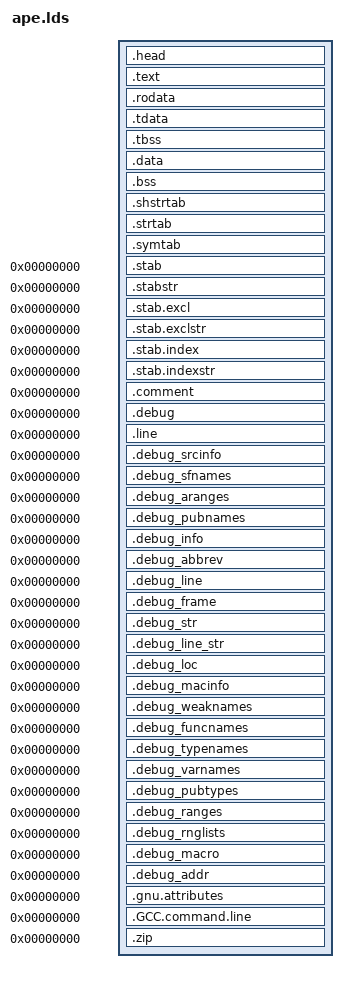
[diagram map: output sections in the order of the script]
ENTRY(_start)
PHDRS {
  Head 1 FLAGS(1|4);
  Cod 1 FLAGS(1|4);
  Rom 1 FLAGS(4);
  Tls 7 FLAGS(2|4);
  Ram 1 FLAGS(2|4);
  stack 0x6474e551 FLAGS(2|4);
}
SECTIONS {
  .head SEGMENT_START("text-segment", 0x400000) + 0 : AT(0x2000) {
    __executable_start = .;
    KEEP(*(.head))
    KEEP(*(.text.head))
    . = ALIGN(. != 0 ? 8 : 0);
    ape_phdrs = .;
    KEEP(*(.elf.phdrs))
    ape_phdrs_end = .;
    . = ALIGN(. != 0 ? 8 : 0);
    ape_note = .;
    KEEP(*(.note.openbsd.ident))
    KEEP(*(.note.netbsd.ident))
    ape_note_end = .;
    KEEP(*(.pe.header))
    ape_pe_sections = .;
    KEEP(*(.pe.sections))
    ape_pe_sections_end = .;
    KEEP(*(.macho))
    . = ALIGN(. != 0 ? 8 : 0);
    ape_macho_end = .;
    KEEP(*(.ape.loader))
    . = ALIGN(. != 0 ? 1 : 0);
    KEEP(*(.ape.pad.head))
    . = ALIGN(. != 0 ? (((1 & 4) == 4) || ((1 & 2) == 2) ? CONSTANT(COMMONPAGESIZE) : 16) : 0);
    _ehead = .;
  } :Head
  .text . : {
    BYTE(0x90)
    *(.text.real)
    KEEP(*(SORT_BY_NAME(.sort.text.real.*)))
    _ereal = .;
    . += 1;
    *(.start)
    KEEP(*(.initprologue))
    KEEP(*(SORT_BY_NAME(.init.*)))
    KEEP(*(.init))
    KEEP(*(.initepilogue))
    *(.plt)
    *(.plt.got)
    *(.iplt)
    *(.text.startup .text.startup.*)
    *(.text.exit .text.exit.*)
    *(.text.unlikely .text.*_unlikely .text.unlikely.*)
    *(SORT_BY_ALIGNMENT(.text.antiquity))
    *(SORT_BY_ALIGNMENT(.text.antiquity.*))
    KEEP(*(.textwindowsprologue))
    *(.text.windows)
    KEEP(*(.textwindowsepilogue))
    *(SORT_BY_ALIGNMENT(.text.modernity))
    *(SORT_BY_ALIGNMENT(.text.modernity.*))
    *(SORT_BY_ALIGNMENT(.text.hot))
    *(SORT_BY_ALIGNMENT(.text.hot.*))
    KEEP(*(.keep.text))
    *(.text .stub .text.*)
    KEEP(*(SORT_BY_NAME(.sort.text.*)))
    KEEP(*(.ape.pad.test));
    *(.test.unlikely)
    *(.test .test.*)
    KEEP(*(.ape.pad.privileged));
    . = ALIGN(__privileged_end > __privileged_start ? CONSTANT(COMMONPAGESIZE) : 0);
    __privileged_start = .;
    *(.privileged)
    __privileged_end = .;
    KEEP(*(.ape.pad.text))
    . = ALIGN(. != 0 ? CONSTANT(COMMONPAGESIZE) : 0);
  } :Cod
  .rodata ALIGN(CONSTANT(COMMONPAGESIZE)) : {
    KEEP(*(.rodata.pytab.0));
    KEEP(*(.rodata.pytab.1));
    KEEP(*(.rodata.pytab.2));
    *(.rodata .rodata.*)
    *(.ubsan.types)
    *(.ubsan.data)
    __notices = .;
    KEEP(*(.notice))
    BYTE(0);
    BYTE(10);
    BYTE(10);
    KEEP(*(.initroprologue))
    KEEP(*(SORT_BY_NAME(.initro.*)))
    KEEP(*(.initroepilogue))
    KEEP(*(SORT_BY_NAME(.sort.rodata.*)))
    . = ALIGN(. != 0 ? CONSTANT(COMMONPAGESIZE) : 0);
  } :Rom
  .tdata . : {
    _tdata_start = .;
    *(SORT_BY_ALIGNMENT(.tdata))
    *(SORT_BY_ALIGNMENT(.tdata.*))
    _tdata_end = .;
    KEEP(*(.ape.pad.rodata))
    . = ALIGN(. != 0 ? CONSTANT(COMMONPAGESIZE) : 0);
    _etext = .;
    PROVIDE(etext = .);
  } :Tls :Rom
  . = ALIGN(CONSTANT(COMMONPAGESIZE));
  .tbss : {
    _tbss_start = .;
    *(SORT_BY_ALIGNMENT(.tbss))
    *(SORT_BY_ALIGNMENT(.tbss.*))
    KEEP(*(.fstls))
    _tbss_end = .;
  } :Tls
  .data . : {
    KEEP(*(.dataprologue))
    *(.data .data.*)
    *(.gnu_extab)
    *(.gcc_except_table .gcc_except_table.*)
    *(.exception_ranges*)
    *(.PyRuntime)
    *(.subrs)
    KEEP(*(SORT_BY_NAME(.sort.data.*)))
    . += . > 0 ? 1 : 0;
    . = ALIGN(. != 0 ? 8 : 0);
    __got_start = .;
    *(.got)
    __got_end = .;
    *(.got.plt)
    . = ALIGN(. != 0 ? 8 : 0);
    __init_array_start = .;
    KEEP(*(.preinit_array))
    KEEP(*(SORT_BY_INIT_PRIORITY(.init_array.*)
           SORT_BY_INIT_PRIORITY(.ctors.*)))
    KEEP(*(.init_array))
    KEEP(*(.ctors))
    __init_array_end = .;
    . = ALIGN(. != 0 ? 8 : 0);
    __fini_array_start = .;
    KEEP(*(SORT_BY_INIT_PRIORITY(.fini_array.*)
           SORT_BY_INIT_PRIORITY(.dtors.*)))
    KEEP(*(.fini_array))
    KEEP(*(.dtors))
    __fini_array_end = .;
    . = ALIGN(. != 0 ? 8 : 0);
    KEEP(*(SORT_BY_NAME(.piro.relo.sort.*)))
    . = ALIGN(. != 0 ? 8 : 0);
    KEEP(*(SORT_BY_NAME(.piro.data.sort.*)))
    KEEP(*(.piro.pad.data))
    *(.igot.plt)
    KEEP(*(.dataepilogue))
    . = ALIGN(. != 0 ? CONSTANT(COMMONPAGESIZE) : 0);
    _edata = .;
    PROVIDE(edata = .);
    _ezip = .;
  } :Ram
  . = ALIGN(CONSTANT(COMMONPAGESIZE));
  .bss : {
    KEEP(*(.bssprologue))
    KEEP(*(SORT_BY_NAME(.piro.bss.init.*)))
    *(.piro.bss)
    KEEP(*(SORT_BY_NAME(.piro.bss.sort.*)))
    __piro_end = .;
    . += . > 0 ? 1 : 0;
    *(SORT_BY_ALIGNMENT(.bss))
    *(SORT_BY_ALIGNMENT(.bss.*))
    *(COMMON)
    KEEP(*(SORT_BY_NAME(.sort.bss.*)))
    KEEP(*(.bssepilogue))
    . = ALIGN(. != 0 ? CONSTANT(COMMONPAGESIZE) : 0);
  } :Ram
  . = ALIGN(CONSTANT(COMMONPAGESIZE));
  _end = .;
  PROVIDE(end = .);
  .shstrtab : { *(.shstrtab) }
  .strtab : { *(.strtab) }
  .symtab : { *(.symtab) }
  .stab 0 : { *(.stab) }
  .stabstr 0 : { *(.stabstr) }
  .stab.excl 0 : { *(.stab.excl) }
  .stab.exclstr 0 : { *(.stab.exclstr) }
  .stab.index 0 : { *(.stab.index) }
  .stab.indexstr 0 : { *(.stab.indexstr) }
  .comment 0 : { *(.comment) }
  .debug 0 : { *(.debug) }
  .line 0 : { *(.line) }
  .debug_srcinfo 0 : { *(.debug_srcinfo) }
  .debug_sfnames 0 : { *(.debug_sfnames) }
  .debug_aranges 0 : { *(.debug_aranges) }
  .debug_pubnames 0 : { *(.debug_pubnames) }
  .debug_info 0 : { *(.debug_info .gnu.linkonce.wi.*) }
  .debug_abbrev 0 : { *(.debug_abbrev) }
  .debug_line 0 : { *(.debug_line .debug_line.* .debug_line_end ) }
  .debug_frame 0 : { *(.debug_frame) }
  .debug_str 0 : { *(.debug_str) }
  .debug_line_str 0 : { *(.debug_line_str) }
  .debug_loc 0 : { *(.debug_loc) }
  .debug_macinfo 0 : { *(.debug_macinfo) }
  .debug_weaknames 0 : { *(.debug_weaknames) }
  .debug_funcnames 0 : { *(.debug_funcnames) }
  .debug_typenames 0 : { *(.debug_typenames) }
  .debug_varnames 0 : { *(.debug_varnames) }
  .debug_pubtypes 0 : { *(.debug_pubtypes) }
  .debug_ranges 0 : { *(.debug_ranges) }
  .debug_rnglists 0 : { *(.debug_rnglists) }
  .debug_macro 0 : { *(.debug_macro) }
  .debug_addr 0 : { *(.debug_addr) }
  .gnu.attributes 0 : { KEEP(*(.gnu.attributes)) }
  .GCC.command.line 0 : { *(.GCC.command.line) }
  .zip 0 : {
    KEEP(*(.zip.file))
    __zip_cdir_start = .;
    KEEP(*(.zip.cdir))
    __zip_cdir_size = . - __zip_cdir_start;
    KEEP(*(.zip.eocd))
  }
  /DISCARD/ : {
    *(.idata.ro);
    *(.idata.ro.*)
    *(.piro.data.sort.iat.*)
    *(__patchable_function_entries)
    *(.note.gnu.property)
    *(__mcount_loc)
    *(.rela.dyn)
    *(.discard)
    *(.yoink)
  }
}
ape_pe_filealignment = 512;
ape_pe_sectionalignment = 4096;
ape_pe_sizeofheaders = SIZEOF(.head);
ape_pe_sizeofimage = (((_end - __executable_start) + (ape_pe_sectionalignment) - 1) & -(ape_pe_sectionalignment));
HIDDEN(ape_elf_entry = (_start)); HIDDEN(ape_elf_entry_bcs0 = (((((((_start) >> ((0) * 8)) >> 0) & 0x7) + 0x30) << 24) | ((((((_start) >> ((0) * 8)) >> 3) & 0x7) + 0x30) << 16) | (((((((_start) >> ((0) * 8)) & 0xff) >> 6) & 0x7) + 0x30) << 8) | 0x5c)); HIDDEN(ape_elf_entry_bcs1 = (((((((_start) >> ((1) * 8)) >> 0) & 0x7) + 0x30) << 24) | ((((((_start) >> ((1) * 8)) >> 3) & 0x7) + 0x30) << 16) | (((((((_start) >> ((1) * 8)) & 0xff) >> 6) & 0x7) + 0x30) << 8) | 0x5c)); HIDDEN(ape_elf_entry_bcs2 = (((((((_start) >> ((2) * 8)) >> 0) & 0x7) + 0x30) << 24) | ((((((_start) >> ((2) * 8)) >> 3) & 0x7) + 0x30) << 16) | (((((((_start) >> ((2) * 8)) & 0xff) >> 6) & 0x7) + 0x30) << 8) | 0x5c)); HIDDEN(ape_elf_entry_bcs3 = (((((((_start) >> ((3) * 8)) >> 0) & 0x7) + 0x30) << 24) | ((((((_start) >> ((3) * 8)) >> 3) & 0x7) + 0x30) << 16) | (((((((_start) >> ((3) * 8)) & 0xff) >> 6) & 0x7) + 0x30) << 8) | 0x5c)); HIDDEN(ape_elf_entry_bcs4 = (((((((_start) >> ((4) * 8)) >> 0) & 0x7) + 0x30) << 24) | ((((((_start) >> ((4) * 8)) >> 3) & 0x7) + 0x30) << 16) | (((((((_start) >> ((4) * 8)) & 0xff) >> 6) & 0x7) + 0x30) << 8) | 0x5c)); HIDDEN(ape_elf_entry_bcs5 = (((((((_start) >> ((5) * 8)) >> 0) & 0x7) + 0x30) << 24) | ((((((_start) >> ((5) * 8)) >> 3) & 0x7) + 0x30) << 16) | (((((((_start) >> ((5) * 8)) & 0xff) >> 6) & 0x7) + 0x30) << 8) | 0x5c)); HIDDEN(ape_elf_entry_bcs6 = (((((((_start) >> ((6) * 8)) >> 0) & 0x7) + 0x30) << 24) | ((((((_start) >> ((6) * 8)) >> 3) & 0x7) + 0x30) << 16) | (((((((_start) >> ((6) * 8)) & 0xff) >> 6) & 0x7) + 0x30) << 8) | 0x5c)); HIDDEN(ape_elf_entry_bcs7 = (((((((_start) >> ((7) * 8)) >> 0) & 0x7) + 0x30) << 24) | ((((((_start) >> ((7) * 8)) >> 3) & 0x7) + 0x30) << 16) | (((((((_start) >> ((7) * 8)) & 0xff) >> 6) & 0x7) + 0x30) << 8) | 0x5c));
HIDDEN(ape_elf_phoff = (((ape_phdrs) - (0x400000)))); HIDDEN(ape_elf_phoff_bcs0 = (((((((((ape_phdrs) - (0x400000))) >> ((0) * 8)) >> 0) & 0x7) + 0x30) << 24) | ((((((((ape_phdrs) - (0x400000))) >> ((0) * 8)) >> 3) & 0x7) + 0x30) << 16) | (((((((((ape_phdrs) - (0x400000))) >> ((0) * 8)) & 0xff) >> 6) & 0x7) + 0x30) << 8) | 0x5c)); HIDDEN(ape_elf_phoff_bcs1 = (((((((((ape_phdrs) - (0x400000))) >> ((1) * 8)) >> 0) & 0x7) + 0x30) << 24) | ((((((((ape_phdrs) - (0x400000))) >> ((1) * 8)) >> 3) & 0x7) + 0x30) << 16) | (((((((((ape_phdrs) - (0x400000))) >> ((1) * 8)) & 0xff) >> 6) & 0x7) + 0x30) << 8) | 0x5c)); HIDDEN(ape_elf_phoff_bcs2 = (((((((((ape_phdrs) - (0x400000))) >> ((2) * 8)) >> 0) & 0x7) + 0x30) << 24) | ((((((((ape_phdrs) - (0x400000))) >> ((2) * 8)) >> 3) & 0x7) + 0x30) << 16) | (((((((((ape_phdrs) - (0x400000))) >> ((2) * 8)) & 0xff) >> 6) & 0x7) + 0x30) << 8) | 0x5c)); HIDDEN(ape_elf_phoff_bcs3 = (((((((((ape_phdrs) - (0x400000))) >> ((3) * 8)) >> 0) & 0x7) + 0x30) << 24) | ((((((((ape_phdrs) - (0x400000))) >> ((3) * 8)) >> 3) & 0x7) + 0x30) << 16) | (((((((((ape_phdrs) - (0x400000))) >> ((3) * 8)) & 0xff) >> 6) & 0x7) + 0x30) << 8) | 0x5c)); HIDDEN(ape_elf_phoff_bcs4 = (((((((((ape_phdrs) - (0x400000))) >> ((4) * 8)) >> 0) & 0x7) + 0x30) << 24) | ((((((((ape_phdrs) - (0x400000))) >> ((4) * 8)) >> 3) & 0x7) + 0x30) << 16) | (((((((((ape_phdrs) - (0x400000))) >> ((4) * 8)) & 0xff) >> 6) & 0x7) + 0x30) << 8) | 0x5c)); HIDDEN(ape_elf_phoff_bcs5 = (((((((((ape_phdrs) - (0x400000))) >> ((5) * 8)) >> 0) & 0x7) + 0x30) << 24) | ((((((((ape_phdrs) - (0x400000))) >> ((5) * 8)) >> 3) & 0x7) + 0x30) << 16) | (((((((((ape_phdrs) - (0x400000))) >> ((5) * 8)) & 0xff) >> 6) & 0x7) + 0x30) << 8) | 0x5c)); HIDDEN(ape_elf_phoff_bcs6 = (((((((((ape_phdrs) - (0x400000))) >> ((6) * 8)) >> 0) & 0x7) + 0x30) << 24) | ((((((((ape_phdrs) - (0x400000))) >> ((6) * 8)) >> 3) & 0x7) + 0x30) << 16) | (((((((((ape_phdrs) - (0x400000))) >> ((6) * 8)) & 0xff) >> 6) & 0x7) + 0x30) << 8) | 0x5c)); HIDDEN(ape_elf_phoff_bcs7 = (((((((((ape_phdrs) - (0x400000))) >> ((7) * 8)) >> 0) & 0x7) + 0x30) << 24) | ((((((((ape_phdrs) - (0x400000))) >> ((7) * 8)) >> 3) & 0x7) + 0x30) << 16) | (((((((((ape_phdrs) - (0x400000))) >> ((7) * 8)) & 0xff) >> 6) & 0x7) + 0x30) << 8) | 0x5c));
HIDDEN(ape_elf_shoff = (0)); HIDDEN(ape_elf_shoff_bcs0 = (((((((0) >> ((0) * 8)) >> 0) & 0x7) + 0x30) << 24) | ((((((0) >> ((0) * 8)) >> 3) & 0x7) + 0x30) << 16) | (((((((0) >> ((0) * 8)) & 0xff) >> 6) & 0x7) + 0x30) << 8) | 0x5c)); HIDDEN(ape_elf_shoff_bcs1 = (((((((0) >> ((1) * 8)) >> 0) & 0x7) + 0x30) << 24) | ((((((0) >> ((1) * 8)) >> 3) & 0x7) + 0x30) << 16) | (((((((0) >> ((1) * 8)) & 0xff) >> 6) & 0x7) + 0x30) << 8) | 0x5c)); HIDDEN(ape_elf_shoff_bcs2 = (((((((0) >> ((2) * 8)) >> 0) & 0x7) + 0x30) << 24) | ((((((0) >> ((2) * 8)) >> 3) & 0x7) + 0x30) << 16) | (((((((0) >> ((2) * 8)) & 0xff) >> 6) & 0x7) + 0x30) << 8) | 0x5c)); HIDDEN(ape_elf_shoff_bcs3 = (((((((0) >> ((3) * 8)) >> 0) & 0x7) + 0x30) << 24) | ((((((0) >> ((3) * 8)) >> 3) & 0x7) + 0x30) << 16) | (((((((0) >> ((3) * 8)) & 0xff) >> 6) & 0x7) + 0x30) << 8) | 0x5c)); HIDDEN(ape_elf_shoff_bcs4 = (((((((0) >> ((4) * 8)) >> 0) & 0x7) + 0x30) << 24) | ((((((0) >> ((4) * 8)) >> 3) & 0x7) + 0x30) << 16) | (((((((0) >> ((4) * 8)) & 0xff) >> 6) & 0x7) + 0x30) << 8) | 0x5c)); HIDDEN(ape_elf_shoff_bcs5 = (((((((0) >> ((5) * 8)) >> 0) & 0x7) + 0x30) << 24) | ((((((0) >> ((5) * 8)) >> 3) & 0x7) + 0x30) << 16) | (((((((0) >> ((5) * 8)) & 0xff) >> 6) & 0x7) + 0x30) << 8) | 0x5c)); HIDDEN(ape_elf_shoff_bcs6 = (((((((0) >> ((6) * 8)) >> 0) & 0x7) + 0x30) << 24) | ((((((0) >> ((6) * 8)) >> 3) & 0x7) + 0x30) << 16) | (((((((0) >> ((6) * 8)) & 0xff) >> 6) & 0x7) + 0x30) << 8) | 0x5c)); HIDDEN(ape_elf_shoff_bcs7 = (((((((0) >> ((7) * 8)) >> 0) & 0x7) + 0x30) << 24) | ((((((0) >> ((7) * 8)) >> 3) & 0x7) + 0x30) << 16) | (((((((0) >> ((7) * 8)) & 0xff) >> 6) & 0x7) + 0x30) << 8) | 0x5c));
HIDDEN(ape_elf_phnum = ((ape_phdrs_end - ape_phdrs) / 56)); HIDDEN(ape_elf_phnum_bcs0 = ((((((((ape_phdrs_end - ape_phdrs) / 56) >> ((0) * 8)) >> 0) & 0x7) + 0x30) << 24) | (((((((ape_phdrs_end - ape_phdrs) / 56) >> ((0) * 8)) >> 3) & 0x7) + 0x30) << 16) | ((((((((ape_phdrs_end - ape_phdrs) / 56) >> ((0) * 8)) & 0xff) >> 6) & 0x7) + 0x30) << 8) | 0x5c)); HIDDEN(ape_elf_phnum_bcs1 = ((((((((ape_phdrs_end - ape_phdrs) / 56) >> ((1) * 8)) >> 0) & 0x7) + 0x30) << 24) | (((((((ape_phdrs_end - ape_phdrs) / 56) >> ((1) * 8)) >> 3) & 0x7) + 0x30) << 16) | ((((((((ape_phdrs_end - ape_phdrs) / 56) >> ((1) * 8)) & 0xff) >> 6) & 0x7) + 0x30) << 8) | 0x5c)); HIDDEN(ape_elf_phnum_bcs2 = ((((((((ape_phdrs_end - ape_phdrs) / 56) >> ((2) * 8)) >> 0) & 0x7) + 0x30) << 24) | (((((((ape_phdrs_end - ape_phdrs) / 56) >> ((2) * 8)) >> 3) & 0x7) + 0x30) << 16) | ((((((((ape_phdrs_end - ape_phdrs) / 56) >> ((2) * 8)) & 0xff) >> 6) & 0x7) + 0x30) << 8) | 0x5c)); HIDDEN(ape_elf_phnum_bcs3 = ((((((((ape_phdrs_end - ape_phdrs) / 56) >> ((3) * 8)) >> 0) & 0x7) + 0x30) << 24) | (((((((ape_phdrs_end - ape_phdrs) / 56) >> ((3) * 8)) >> 3) & 0x7) + 0x30) << 16) | ((((((((ape_phdrs_end - ape_phdrs) / 56) >> ((3) * 8)) & 0xff) >> 6) & 0x7) + 0x30) << 8) | 0x5c));
HIDDEN(ape_elf_shnum = (0)); HIDDEN(ape_elf_shnum_bcs0 = (((((((0) >> ((0) * 8)) >> 0) & 0x7) + 0x30) << 24) | ((((((0) >> ((0) * 8)) >> 3) & 0x7) + 0x30) << 16) | (((((((0) >> ((0) * 8)) & 0xff) >> 6) & 0x7) + 0x30) << 8) | 0x5c)); HIDDEN(ape_elf_shnum_bcs1 = (((((((0) >> ((1) * 8)) >> 0) & 0x7) + 0x30) << 24) | ((((((0) >> ((1) * 8)) >> 3) & 0x7) + 0x30) << 16) | (((((((0) >> ((1) * 8)) & 0xff) >> 6) & 0x7) + 0x30) << 8) | 0x5c)); HIDDEN(ape_elf_shnum_bcs2 = (((((((0) >> ((2) * 8)) >> 0) & 0x7) + 0x30) << 24) | ((((((0) >> ((2) * 8)) >> 3) & 0x7) + 0x30) << 16) | (((((((0) >> ((2) * 8)) & 0xff) >> 6) & 0x7) + 0x30) << 8) | 0x5c)); HIDDEN(ape_elf_shnum_bcs3 = (((((((0) >> ((3) * 8)) >> 0) & 0x7) + 0x30) << 24) | ((((((0) >> ((3) * 8)) >> 3) & 0x7) + 0x30) << 16) | (((((((0) >> ((3) * 8)) & 0xff) >> 6) & 0x7) + 0x30) << 8) | 0x5c));
HIDDEN(ape_elf_shstrndx = (0)); HIDDEN(ape_elf_shstrndx_bcs0 = (((((((0) >> ((0) * 8)) >> 0) & 0x7) + 0x30) << 24) | ((((((0) >> ((0) * 8)) >> 3) & 0x7) + 0x30) << 16) | (((((((0) >> ((0) * 8)) & 0xff) >> 6) & 0x7) + 0x30) << 8) | 0x5c)); HIDDEN(ape_elf_shstrndx_bcs1 = (((((((0) >> ((1) * 8)) >> 0) & 0x7) + 0x30) << 24) | ((((((0) >> ((1) * 8)) >> 3) & 0x7) + 0x30) << 16) | (((((((0) >> ((1) * 8)) & 0xff) >> 6) & 0x7) + 0x30) << 8) | 0x5c)); HIDDEN(ape_elf_shstrndx_bcs2 = (((((((0) >> ((2) * 8)) >> 0) & 0x7) + 0x30) << 24) | ((((((0) >> ((2) * 8)) >> 3) & 0x7) + 0x30) << 16) | (((((((0) >> ((2) * 8)) & 0xff) >> 6) & 0x7) + 0x30) << 8) | 0x5c)); HIDDEN(ape_elf_shstrndx_bcs3 = (((((((0) >> ((3) * 8)) >> 0) & 0x7) + 0x30) << 24) | ((((((0) >> ((3) * 8)) >> 3) & 0x7) + 0x30) << 16) | (((((((0) >> ((3) * 8)) & 0xff) >> 6) & 0x7) + 0x30) << 8) | 0x5c));
_tls_size = _tbss_end - _tdata_start;
_tdata_size = _tdata_end - _tdata_start;
_tbss_size = _tbss_end - _tbss_start;
_tbss_offset = _tbss_start - _tdata_start;
_tls_content = (_tdata_end - _tdata_start) + (_tbss_end - _tbss_start);
_tdata_align = ALIGNOF(.tdata);
_tbss_align = ALIGNOF(.tbss);
_tls_align = ((((ALIGNOF(.tbss)) < (ALIGNOF(.tdata)) ? (ALIGNOF(.tdata)) : (ALIGNOF(.tbss)))) < (64) ? (64) : (((ALIGNOF(.tbss)) < (ALIGNOF(.tdata)) ? (ALIGNOF(.tdata)) : (ALIGNOF(.tbss)))));
ape_cod_offset = 0;
ape_cod_vaddr = ADDR(.head);
ape_cod_paddr = LOADADDR(.head);
ape_cod_filesz = ADDR(.rodata) - ADDR(.head);
ape_cod_memsz = ape_cod_filesz;
ape_cod_align = CONSTANT(COMMONPAGESIZE);
ape_cod_rva = ((ape_cod_vaddr) - (0x400000));
ape_rom_vaddr = ADDR(.rodata);
ape_rom_offset = ape_rom_vaddr - __executable_start;
ape_rom_paddr = LOADADDR(.rodata);
ape_rom_filesz = ADDR(.tbss) - ADDR(.rodata);
ape_rom_memsz = ape_rom_filesz;
ape_rom_align = CONSTANT(COMMONPAGESIZE);
ape_rom_rva = ((ape_rom_vaddr) - (0x400000));
ape_ram_vaddr = ADDR(.data);
ape_ram_offset = ape_ram_vaddr - __executable_start;
ape_ram_paddr = LOADADDR(.data);
ape_ram_filesz = ADDR(.bss) - ADDR(.data);
ape_ram_memsz = _end - ADDR(.data);
ape_ram_align = CONSTANT(COMMONPAGESIZE);
ape_ram_rva = ((ape_ram_vaddr) - (0x400000));
ape_stack_pf = DEFINED(ape_stack_pf) ? ape_stack_pf : 4 | 2;
ape_stack_prot = ((4 & (ape_stack_pf)) >> 2 | (2 & (ape_stack_pf)) | (1 & (ape_stack_pf)) << 2);
ape_stack_offset = 0;
ape_stack_vaddr = DEFINED(ape_stack_vaddr) ? ape_stack_vaddr : 0x700000000000;
ape_stack_paddr = ape_ram_paddr + ape_ram_filesz;
ape_stack_filesz = 0;
ape_stack_memsz = DEFINED(ape_stack_memsz) ? ape_stack_memsz : 8 * 1024 * 1024;
ape_note_offset = ape_cod_offset + (ape_note - ape_cod_vaddr);
ape_note_filesz = ape_note_end - ape_note;
ape_note_memsz = ape_note_filesz;
ape_text_vaddr = ADDR(.text);
ape_text_offset = ape_text_vaddr - __executable_start;
ape_text_paddr = LOADADDR(.text);
ape_text_filesz = ADDR(.rodata) - ADDR(.text);
ape_text_memsz = ape_text_filesz;
ape_text_align = CONSTANT(COMMONPAGESIZE);
ape_text_rva = ((ape_text_vaddr) - (0x400000));
HIDDEN(ape_loader_dd_skip_bcs0 = (((DEFINED(ape_loader) ? ((ape_loader) - (0x400000)) / 64 : 0)) < 10000 ? (((((DEFINED(ape_loader) ? ((ape_loader) - (0x400000)) / 64 : 0) + (DEFINED(ape_loader) ? ((ape_loader) - (0x400000)) / 64 : 0) * 10000))) < 10000 ? 0x20202020 : (((DEFINED(ape_loader) ? ((ape_loader) - (0x400000)) / 64 : 0) + (DEFINED(ape_loader) ? ((ape_loader) - (0x400000)) / 64 : 0) * 10000)) < 100000 ? 0x20202030 + (((DEFINED(ape_loader) ? ((ape_loader) - (0x400000)) / 64 : 0) + (DEFINED(ape_loader) ? ((ape_loader) - (0x400000)) / 64 : 0) * 10000)) % 10 : (((DEFINED(ape_loader) ? ((ape_loader) - (0x400000)) / 64 : 0) + (DEFINED(ape_loader) ? ((ape_loader) - (0x400000)) / 64 : 0) * 10000)) < 1000000 ? 0x20203030 + ((((DEFINED(ape_loader) ? ((ape_loader) - (0x400000)) / 64 : 0) + (DEFINED(ape_loader) ? ((ape_loader) - (0x400000)) / 64 : 0) * 10000)) / 10) % 10 + (((DEFINED(ape_loader) ? ((ape_loader) - (0x400000)) / 64 : 0) + (DEFINED(ape_loader) ? ((ape_loader) - (0x400000)) / 64 : 0) * 10000)) % 10 * 0x100 : (((DEFINED(ape_loader) ? ((ape_loader) - (0x400000)) / 64 : 0) + (DEFINED(ape_loader) ? ((ape_loader) - (0x400000)) / 64 : 0) * 10000)) < 10000000 ? 0x20303030 + ((((DEFINED(ape_loader) ? ((ape_loader) - (0x400000)) / 64 : 0) + (DEFINED(ape_loader) ? ((ape_loader) - (0x400000)) / 64 : 0) * 10000)) / 100) % 10 + ((((DEFINED(ape_loader) ? ((ape_loader) - (0x400000)) / 64 : 0) + (DEFINED(ape_loader) ? ((ape_loader) - (0x400000)) / 64 : 0) * 10000)) / 10) % 10 * 0x100 + (((DEFINED(ape_loader) ? ((ape_loader) - (0x400000)) / 64 : 0) + (DEFINED(ape_loader) ? ((ape_loader) - (0x400000)) / 64 : 0) * 10000)) % 10 * 0x10000 : (((DEFINED(ape_loader) ? ((ape_loader) - (0x400000)) / 64 : 0) + (DEFINED(ape_loader) ? ((ape_loader) - (0x400000)) / 64 : 0) * 10000)) < 100000000 ? 0x30303030 + ((((DEFINED(ape_loader) ? ((ape_loader) - (0x400000)) / 64 : 0) + (DEFINED(ape_loader) ? ((ape_loader) - (0x400000)) / 64 : 0) * 10000)) / 1000) % 10 + ((((DEFINED(ape_loader) ? ((ape_loader) - (0x400000)) / 64 : 0) + (DEFINED(ape_loader) ? ((ape_loader) - (0x400000)) / 64 : 0) * 10000)) / 100) % 10 * 0x100 + ((((DEFINED(ape_loader) ? ((ape_loader) - (0x400000)) / 64 : 0) + (DEFINED(ape_loader) ? ((ape_loader) - (0x400000)) / 64 : 0) * 10000)) / 10) % 10 * 0x10000 + (((DEFINED(ape_loader) ? ((ape_loader) - (0x400000)) / 64 : 0) + (DEFINED(ape_loader) ? ((ape_loader) - (0x400000)) / 64 : 0) * 10000)) % 10 * 0x1000000 : 0xffffffffffffffff) | 0x10 : (DEFINED(ape_loader) ? ((ape_loader) - (0x400000)) / 64 : 0) < 100000 ? ((((((DEFINED(ape_loader) ? ((ape_loader) - (0x400000)) / 64 : 0) / 10) + ((DEFINED(ape_loader) ? ((ape_loader) - (0x400000)) / 64 : 0) / 10) * 10000))) < 10000 ? 0x20202020 : ((((DEFINED(ape_loader) ? ((ape_loader) - (0x400000)) / 64 : 0) / 10) + ((DEFINED(ape_loader) ? ((ape_loader) - (0x400000)) / 64 : 0) / 10) * 10000)) < 100000 ? 0x20202030 + ((((DEFINED(ape_loader) ? ((ape_loader) - (0x400000)) / 64 : 0) / 10) + ((DEFINED(ape_loader) ? ((ape_loader) - (0x400000)) / 64 : 0) / 10) * 10000)) % 10 : ((((DEFINED(ape_loader) ? ((ape_loader) - (0x400000)) / 64 : 0) / 10) + ((DEFINED(ape_loader) ? ((ape_loader) - (0x400000)) / 64 : 0) / 10) * 10000)) < 1000000 ? 0x20203030 + (((((DEFINED(ape_loader) ? ((ape_loader) - (0x400000)) / 64 : 0) / 10) + ((DEFINED(ape_loader) ? ((ape_loader) - (0x400000)) / 64 : 0) / 10) * 10000)) / 10) % 10 + ((((DEFINED(ape_loader) ? ((ape_loader) - (0x400000)) / 64 : 0) / 10) + ((DEFINED(ape_loader) ? ((ape_loader) - (0x400000)) / 64 : 0) / 10) * 10000)) % 10 * 0x100 : ((((DEFINED(ape_loader) ? ((ape_loader) - (0x400000)) / 64 : 0) / 10) + ((DEFINED(ape_loader) ? ((ape_loader) - (0x400000)) / 64 : 0) / 10) * 10000)) < 10000000 ? 0x20303030 + (((((DEFINED(ape_loader) ? ((ape_loader) - (0x400000)) / 64 : 0) / 10) + ((DEFINED(ape_loader) ? ((ape_loader) - (0x400000)) / 64 : 0) / 10) * 10000)) / 100) % 10 + (((((DEFINED(ape_loader) ? ((ape_loader) - (0x400000)) / 64 : 0) / 10) + ((DEFINED(ape_loader) ? ((ape_loader) - (0x400000)) / 64 : 0) / 10) * 10000)) / 10) % 10 * 0x100 + ((((DEFINED(ape_loader) ? ((ape_loader) - (0x400000)) / 64 : 0) / 10) + ((DEFINED(ape_loader) ? ((ape_loader) - (0x400000)) / 64 : 0) / 10) * 10000)) % 10 * 0x10000 : ((((DEFINED(ape_loader) ? ((ape_loader) - (0x400000)) / 64 : 0) / 10) + ((DEFINED(ape_loader) ? ((ape_loader) - (0x400000)) / 64 : 0) / 10) * 10000)) < 100000000 ? 0x30303030 + (((((DEFINED(ape_loader) ? ((ape_loader) - (0x400000)) / 64 : 0) / 10) + ((DEFINED(ape_loader) ? ((ape_loader) - (0x400000)) / 64 : 0) / 10) * 10000)) / 1000) % 10 + (((((DEFINED(ape_loader) ? ((ape_loader) - (0x400000)) / 64 : 0) / 10) + ((DEFINED(ape_loader) ? ((ape_loader) - (0x400000)) / 64 : 0) / 10) * 10000)) / 100) % 10 * 0x100 + (((((DEFINED(ape_loader) ? ((ape_loader) - (0x400000)) / 64 : 0) / 10) + ((DEFINED(ape_loader) ? ((ape_loader) - (0x400000)) / 64 : 0) / 10) * 10000)) / 10) % 10 * 0x10000 + ((((DEFINED(ape_loader) ? ((ape_loader) - (0x400000)) / 64 : 0) / 10) + ((DEFINED(ape_loader) ? ((ape_loader) - (0x400000)) / 64 : 0) / 10) * 10000)) % 10 * 0x1000000 : 0xffffffffffffffff) : (DEFINED(ape_loader) ? ((ape_loader) - (0x400000)) / 64 : 0) < 1000000 ? ((((((DEFINED(ape_loader) ? ((ape_loader) - (0x400000)) / 64 : 0) / 100) + ((DEFINED(ape_loader) ? ((ape_loader) - (0x400000)) / 64 : 0) / 100) * 10000))) < 10000 ? 0x20202020 : ((((DEFINED(ape_loader) ? ((ape_loader) - (0x400000)) / 64 : 0) / 100) + ((DEFINED(ape_loader) ? ((ape_loader) - (0x400000)) / 64 : 0) / 100) * 10000)) < 100000 ? 0x20202030 + ((((DEFINED(ape_loader) ? ((ape_loader) - (0x400000)) / 64 : 0) / 100) + ((DEFINED(ape_loader) ? ((ape_loader) - (0x400000)) / 64 : 0) / 100) * 10000)) % 10 : ((((DEFINED(ape_loader) ? ((ape_loader) - (0x400000)) / 64 : 0) / 100) + ((DEFINED(ape_loader) ? ((ape_loader) - (0x400000)) / 64 : 0) / 100) * 10000)) < 1000000 ? 0x20203030 + (((((DEFINED(ape_loader) ? ((ape_loader) - (0x400000)) / 64 : 0) / 100) + ((DEFINED(ape_loader) ? ((ape_loader) - (0x400000)) / 64 : 0) / 100) * 10000)) / 10) % 10 + ((((DEFINED(ape_loader) ? ((ape_loader) - (0x400000)) / 64 : 0) / 100) + ((DEFINED(ape_loader) ? ((ape_loader) - (0x400000)) / 64 : 0) / 100) * 10000)) % 10 * 0x100 : ((((DEFINED(ape_loader) ? ((ape_loader) - (0x400000)) / 64 : 0) / 100) + ((DEFINED(ape_loader) ? ((ape_loader) - (0x400000)) / 64 : 0) / 100) * 10000)) < 10000000 ? 0x20303030 + (((((DEFINED(ape_loader) ? ((ape_loader) - (0x400000)) / 64 : 0) / 100) + ((DEFINED(ape_loader) ? ((ape_loader) - (0x400000)) / 64 : 0) / 100) * 10000)) / 100) % 10 + (((((DEFINED(ape_loader) ? ((ape_loader) - (0x400000)) / 64 : 0) / 100) + ((DEFINED(ape_loader) ? ((ape_loader) - (0x400000)) / 64 : 0) / 100) * 10000)) / 10) % 10 * 0x100 + ((((DEFINED(ape_loader) ? ((ape_loader) - (0x400000)) / 64 : 0) / 100) + ((DEFINED(ape_loader) ? ((ape_loader) - (0x400000)) / 64 : 0) / 100) * 10000)) % 10 * 0x10000 : ((((DEFINED(ape_loader) ? ((ape_loader) - (0x400000)) / 64 : 0) / 100) + ((DEFINED(ape_loader) ? ((ape_loader) - (0x400000)) / 64 : 0) / 100) * 10000)) < 100000000 ? 0x30303030 + (((((DEFINED(ape_loader) ? ((ape_loader) - (0x400000)) / 64 : 0) / 100) + ((DEFINED(ape_loader) ? ((ape_loader) - (0x400000)) / 64 : 0) / 100) * 10000)) / 1000) % 10 + (((((DEFINED(ape_loader) ? ((ape_loader) - (0x400000)) / 64 : 0) / 100) + ((DEFINED(ape_loader) ? ((ape_loader) - (0x400000)) / 64 : 0) / 100) * 10000)) / 100) % 10 * 0x100 + (((((DEFINED(ape_loader) ? ((ape_loader) - (0x400000)) / 64 : 0) / 100) + ((DEFINED(ape_loader) ? ((ape_loader) - (0x400000)) / 64 : 0) / 100) * 10000)) / 10) % 10 * 0x10000 + ((((DEFINED(ape_loader) ? ((ape_loader) - (0x400000)) / 64 : 0) / 100) + ((DEFINED(ape_loader) ? ((ape_loader) - (0x400000)) / 64 : 0) / 100) * 10000)) % 10 * 0x1000000 : 0xffffffffffffffff) : (DEFINED(ape_loader) ? ((ape_loader) - (0x400000)) / 64 : 0) < 10000000 ? ((((((DEFINED(ape_loader) ? ((ape_loader) - (0x400000)) / 64 : 0) / 1000) + ((DEFINED(ape_loader) ? ((ape_loader) - (0x400000)) / 64 : 0) / 1000) * 10000))) < 10000 ? 0x20202020 : ((((DEFINED(ape_loader) ? ((ape_loader) - (0x400000)) / 64 : 0) / 1000) + ((DEFINED(ape_loader) ? ((ape_loader) - (0x400000)) / 64 : 0) / 1000) * 10000)) < 100000 ? 0x20202030 + ((((DEFINED(ape_loader) ? ((ape_loader) - (0x400000)) / 64 : 0) / 1000) + ((DEFINED(ape_loader) ? ((ape_loader) - (0x400000)) / 64 : 0) / 1000) * 10000)) % 10 : ((((DEFINED(ape_loader) ? ((ape_loader) - (0x400000)) / 64 : 0) / 1000) + ((DEFINED(ape_loader) ? ((ape_loader) - (0x400000)) / 64 : 0) / 1000) * 10000)) < 1000000 ? 0x20203030 + (((((DEFINED(ape_loader) ? ((ape_loader) - (0x400000)) / 64 : 0) / 1000) + ((DEFINED(ape_loader) ? ((ape_loader) - (0x400000)) / 64 : 0) / 1000) * 10000)) / 10) % 10 + ((((DEFINED(ape_loader) ? ((ape_loader) - (0x400000)) / 64 : 0) / 1000) + ((DEFINED(ape_loader) ? ((ape_loader) - (0x400000)) / 64 : 0) / 1000) * 10000)) % 10 * 0x100 : ((((DEFINED(ape_loader) ? ((ape_loader) - (0x400000)) / 64 : 0) / 1000) + ((DEFINED(ape_loader) ? ((ape_loader) - (0x400000)) / 64 : 0) / 1000) * 10000)) < 10000000 ? 0x20303030 + (((((DEFINED(ape_loader) ? ((ape_loader) - (0x400000)) / 64 : 0) / 1000) + ((DEFINED(ape_loader) ? ((ape_loader) - (0x400000)) / 64 : 0) / 1000) * 10000)) / 100) % 10 + (((((DEFINED(ape_loader) ? ((ape_loader) - (0x400000)) / 64 : 0) / 1000) + ((DEFINED(ape_loader) ? ((ape_loader) - (0x400000)) / 64 : 0) / 1000) * 10000)) / 10) % 10 * 0x100 + ((((DEFINED(ape_loader) ? ((ape_loader) - (0x400000)) / 64 : 0) / 1000) + ((DEFINED(ape_loader) ? ((ape_loader) - (0x400000)) / 64 : 0) / 1000) * 10000)) % 10 * 0x10000 : ((((DEFINED(ape_loader) ? ((ape_loader) - (0x400000)) / 64 : 0) / 1000) + ((DEFINED(ape_loader) ? ((ape_loader) - (0x400000)) / 64 : 0) / 1000) * 10000)) < 100000000 ? 0x30303030 + (((((DEFINED(ape_loader) ? ((ape_loader) - (0x400000)) / 64 : 0) / 1000) + ((DEFINED(ape_loader) ? ((ape_loader) - (0x400000)) / 64 : 0) / 1000) * 10000)) / 1000) % 10 + (((((DEFINED(ape_loader) ? ((ape_loader) - (0x400000)) / 64 : 0) / 1000) + ((DEFINED(ape_loader) ? ((ape_loader) - (0x400000)) / 64 : 0) / 1000) * 10000)) / 100) % 10 * 0x100 + (((((DEFINED(ape_loader) ? ((ape_loader) - (0x400000)) / 64 : 0) / 1000) + ((DEFINED(ape_loader) ? ((ape_loader) - (0x400000)) / 64 : 0) / 1000) * 10000)) / 10) % 10 * 0x10000 + ((((DEFINED(ape_loader) ? ((ape_loader) - (0x400000)) / 64 : 0) / 1000) + ((DEFINED(ape_loader) ? ((ape_loader) - (0x400000)) / 64 : 0) / 1000) * 10000)) % 10 * 0x1000000 : 0xffffffffffffffff) : (DEFINED(ape_loader) ? ((ape_loader) - (0x400000)) / 64 : 0) < 100000000 ? ((((((DEFINED(ape_loader) ? ((ape_loader) - (0x400000)) / 64 : 0) / 10000) + ((DEFINED(ape_loader) ? ((ape_loader) - (0x400000)) / 64 : 0) / 10000) * 10000))) < 10000 ? 0x20202020 : ((((DEFINED(ape_loader) ? ((ape_loader) - (0x400000)) / 64 : 0) / 10000) + ((DEFINED(ape_loader) ? ((ape_loader) - (0x400000)) / 64 : 0) / 10000) * 10000)) < 100000 ? 0x20202030 + ((((DEFINED(ape_loader) ? ((ape_loader) - (0x400000)) / 64 : 0) / 10000) + ((DEFINED(ape_loader) ? ((ape_loader) - (0x400000)) / 64 : 0) / 10000) * 10000)) % 10 : ((((DEFINED(ape_loader) ? ((ape_loader) - (0x400000)) / 64 : 0) / 10000) + ((DEFINED(ape_loader) ? ((ape_loader) - (0x400000)) / 64 : 0) / 10000) * 10000)) < 1000000 ? 0x20203030 + (((((DEFINED(ape_loader) ? ((ape_loader) - (0x400000)) / 64 : 0) / 10000) + ((DEFINED(ape_loader) ? ((ape_loader) - (0x400000)) / 64 : 0) / 10000) * 10000)) / 10) % 10 + ((((DEFINED(ape_loader) ? ((ape_loader) - (0x400000)) / 64 : 0) / 10000) + ((DEFINED(ape_loader) ? ((ape_loader) - (0x400000)) / 64 : 0) / 10000) * 10000)) % 10 * 0x100 : ((((DEFINED(ape_loader) ? ((ape_loader) - (0x400000)) / 64 : 0) / 10000) + ((DEFINED(ape_loader) ? ((ape_loader) - (0x400000)) / 64 : 0) / 10000) * 10000)) < 10000000 ? 0x20303030 + (((((DEFINED(ape_loader) ? ((ape_loader) - (0x400000)) / 64 : 0) / 10000) + ((DEFINED(ape_loader) ? ((ape_loader) - (0x400000)) / 64 : 0) / 10000) * 10000)) / 100) % 10 + (((((DEFINED(ape_loader) ? ((ape_loader) - (0x400000)) / 64 : 0) / 10000) + ((DEFINED(ape_loader) ? ((ape_loader) - (0x400000)) / 64 : 0) / 10000) * 10000)) / 10) % 10 * 0x100 + ((((DEFINED(ape_loader) ? ((ape_loader) - (0x400000)) / 64 : 0) / 10000) + ((DEFINED(ape_loader) ? ((ape_loader) - (0x400000)) / 64 : 0) / 10000) * 10000)) % 10 * 0x10000 : ((((DEFINED(ape_loader) ? ((ape_loader) - (0x400000)) / 64 : 0) / 10000) + ((DEFINED(ape_loader) ? ((ape_loader) - (0x400000)) / 64 : 0) / 10000) * 10000)) < 100000000 ? 0x30303030 + (((((DEFINED(ape_loader) ? ((ape_loader) - (0x400000)) / 64 : 0) / 10000) + ((DEFINED(ape_loader) ? ((ape_loader) - (0x400000)) / 64 : 0) / 10000) * 10000)) / 1000) % 10 + (((((DEFINED(ape_loader) ? ((ape_loader) - (0x400000)) / 64 : 0) / 10000) + ((DEFINED(ape_loader) ? ((ape_loader) - (0x400000)) / 64 : 0) / 10000) * 10000)) / 100) % 10 * 0x100 + (((((DEFINED(ape_loader) ? ((ape_loader) - (0x400000)) / 64 : 0) / 10000) + ((DEFINED(ape_loader) ? ((ape_loader) - (0x400000)) / 64 : 0) / 10000) * 10000)) / 10) % 10 * 0x10000 + ((((DEFINED(ape_loader) ? ((ape_loader) - (0x400000)) / 64 : 0) / 10000) + ((DEFINED(ape_loader) ? ((ape_loader) - (0x400000)) / 64 : 0) / 10000) * 10000)) % 10 * 0x1000000 : 0xffffffffffffffff) : 0xffffffffffffffff)); HIDDEN(ape_loader_dd_skip_bcs1 = (((DEFINED(ape_loader) ? ((ape_loader) - (0x400000)) / 64 : 0)) < 10000 ? 0x20202020 : (DEFINED(ape_loader) ? ((ape_loader) - (0x400000)) / 64 : 0) < 100000 ? 0x20202030 + (DEFINED(ape_loader) ? ((ape_loader) - (0x400000)) / 64 : 0) % 10 : (DEFINED(ape_loader) ? ((ape_loader) - (0x400000)) / 64 : 0) < 1000000 ? 0x20203030 + ((DEFINED(ape_loader) ? ((ape_loader) - (0x400000)) / 64 : 0) / 10) % 10 + (DEFINED(ape_loader) ? ((ape_loader) - (0x400000)) / 64 : 0) % 10 * 0x100 : (DEFINED(ape_loader) ? ((ape_loader) - (0x400000)) / 64 : 0) < 10000000 ? 0x20303030 + ((DEFINED(ape_loader) ? ((ape_loader) - (0x400000)) / 64 : 0) / 100) % 10 + ((DEFINED(ape_loader) ? ((ape_loader) - (0x400000)) / 64 : 0) / 10) % 10 * 0x100 + (DEFINED(ape_loader) ? ((ape_loader) - (0x400000)) / 64 : 0) % 10 * 0x10000 : (DEFINED(ape_loader) ? ((ape_loader) - (0x400000)) / 64 : 0) < 100000000 ? 0x30303030 + ((DEFINED(ape_loader) ? ((ape_loader) - (0x400000)) / 64 : 0) / 1000) % 10 + ((DEFINED(ape_loader) ? ((ape_loader) - (0x400000)) / 64 : 0) / 100) % 10 * 0x100 + ((DEFINED(ape_loader) ? ((ape_loader) - (0x400000)) / 64 : 0) / 10) % 10 * 0x10000 + (DEFINED(ape_loader) ? ((ape_loader) - (0x400000)) / 64 : 0) % 10 * 0x1000000 : 0xffffffffffffffff));
HIDDEN(ape_loader_dd_count_bcs0 = (((DEFINED(ape_loader_end) ? (((ape_loader_end - ape_loader) + (CONSTANT(COMMONPAGESIZE)) - 1) & -(CONSTANT(COMMONPAGESIZE))) / 64 : 0)) < 10000 ? (((((DEFINED(ape_loader_end) ? (((ape_loader_end - ape_loader) + (CONSTANT(COMMONPAGESIZE)) - 1) & -(CONSTANT(COMMONPAGESIZE))) / 64 : 0) + (DEFINED(ape_loader_end) ? (((ape_loader_end - ape_loader) + (CONSTANT(COMMONPAGESIZE)) - 1) & -(CONSTANT(COMMONPAGESIZE))) / 64 : 0) * 10000))) < 10000 ? 0x20202020 : (((DEFINED(ape_loader_end) ? (((ape_loader_end - ape_loader) + (CONSTANT(COMMONPAGESIZE)) - 1) & -(CONSTANT(COMMONPAGESIZE))) / 64 : 0) + (DEFINED(ape_loader_end) ? (((ape_loader_end - ape_loader) + (CONSTANT(COMMONPAGESIZE)) - 1) & -(CONSTANT(COMMONPAGESIZE))) / 64 : 0) * 10000)) < 100000 ? 0x20202030 + (((DEFINED(ape_loader_end) ? (((ape_loader_end - ape_loader) + (CONSTANT(COMMONPAGESIZE)) - 1) & -(CONSTANT(COMMONPAGESIZE))) / 64 : 0) + (DEFINED(ape_loader_end) ? (((ape_loader_end - ape_loader) + (CONSTANT(COMMONPAGESIZE)) - 1) & -(CONSTANT(COMMONPAGESIZE))) / 64 : 0) * 10000)) % 10 : (((DEFINED(ape_loader_end) ? (((ape_loader_end - ape_loader) + (CONSTANT(COMMONPAGESIZE)) - 1) & -(CONSTANT(COMMONPAGESIZE))) / 64 : 0) + (DEFINED(ape_loader_end) ? (((ape_loader_end - ape_loader) + (CONSTANT(COMMONPAGESIZE)) - 1) & -(CONSTANT(COMMONPAGESIZE))) / 64 : 0) * 10000)) < 1000000 ? 0x20203030 + ((((DEFINED(ape_loader_end) ? (((ape_loader_end - ape_loader) + (CONSTANT(COMMONPAGESIZE)) - 1) & -(CONSTANT(COMMONPAGESIZE))) / 64 : 0) + (DEFINED(ape_loader_end) ? (((ape_loader_end - ape_loader) + (CONSTANT(COMMONPAGESIZE)) - 1) & -(CONSTANT(COMMONPAGESIZE))) / 64 : 0) * 10000)) / 10) % 10 + (((DEFINED(ape_loader_end) ? (((ape_loader_end - ape_loader) + (CONSTANT(COMMONPAGESIZE)) - 1) & -(CONSTANT(COMMONPAGESIZE))) / 64 : 0) + (DEFINED(ape_loader_end) ? (((ape_loader_end - ape_loader) + (CONSTANT(COMMONPAGESIZE)) - 1) & -(CONSTANT(COMMONPAGESIZE))) / 64 : 0) * 10000)) % 10 * 0x100 : (((DEFINED(ape_loader_end) ? (((ape_loader_end - ape_loader) + (CONSTANT(COMMONPAGESIZE)) - 1) & -(CONSTANT(COMMONPAGESIZE))) / 64 : 0) + (DEFINED(ape_loader_end) ? (((ape_loader_end - ape_loader) + (CONSTANT(COMMONPAGESIZE)) - 1) & -(CONSTANT(COMMONPAGESIZE))) / 64 : 0) * 10000)) < 10000000 ? 0x20303030 + ((((DEFINED(ape_loader_end) ? (((ape_loader_end - ape_loader) + (CONSTANT(COMMONPAGESIZE)) - 1) & -(CONSTANT(COMMONPAGESIZE))) / 64 : 0) + (DEFINED(ape_loader_end) ? (((ape_loader_end - ape_loader) + (CONSTANT(COMMONPAGESIZE)) - 1) & -(CONSTANT(COMMONPAGESIZE))) / 64 : 0) * 10000)) / 100) % 10 + ((((DEFINED(ape_loader_end) ? (((ape_loader_end - ape_loader) + (CONSTANT(COMMONPAGESIZE)) - 1) & -(CONSTANT(COMMONPAGESIZE))) / 64 : 0) + (DEFINED(ape_loader_end) ? (((ape_loader_end - ape_loader) + (CONSTANT(COMMONPAGESIZE)) - 1) & -(CONSTANT(COMMONPAGESIZE))) / 64 : 0) * 10000)) / 10) % 10 * 0x100 + (((DEFINED(ape_loader_end) ? (((ape_loader_end - ape_loader) + (CONSTANT(COMMONPAGESIZE)) - 1) & -(CONSTANT(COMMONPAGESIZE))) / 64 : 0) + (DEFINED(ape_loader_end) ? (((ape_loader_end - ape_loader) + (CONSTANT(COMMONPAGESIZE)) - 1) & -(CONSTANT(COMMONPAGESIZE))) / 64 : 0) * 10000)) % 10 * 0x10000 : (((DEFINED(ape_loader_end) ? (((ape_loader_end - ape_loader) + (CONSTANT(COMMONPAGESIZE)) - 1) & -(CONSTANT(COMMONPAGESIZE))) / 64 : 0) + (DEFINED(ape_loader_end) ? (((ape_loader_end - ape_loader) + (CONSTANT(COMMONPAGESIZE)) - 1) & -(CONSTANT(COMMONPAGESIZE))) / 64 : 0) * 10000)) < 100000000 ? 0x30303030 + ((((DEFINED(ape_loader_end) ? (((ape_loader_end - ape_loader) + (CONSTANT(COMMONPAGESIZE)) - 1) & -(CONSTANT(COMMONPAGESIZE))) / 64 : 0) + (DEFINED(ape_loader_end) ? (((ape_loader_end - ape_loader) + (CONSTANT(COMMONPAGESIZE)) - 1) & -(CONSTANT(COMMONPAGESIZE))) / 64 : 0) * 10000)) / 1000) % 10 + ((((DEFINED(ape_loader_end) ? (((ape_loader_end - ape_loader) + (CONSTANT(COMMONPAGESIZE)) - 1) & -(CONSTANT(COMMONPAGESIZE))) / 64 : 0) + (DEFINED(ape_loader_end) ? (((ape_loader_end - ape_loader) + (CONSTANT(COMMONPAGESIZE)) - 1) & -(CONSTANT(COMMONPAGESIZE))) / 64 : 0) * 10000)) / 100) % 10 * 0x100 + ((((DEFINED(ape_loader_end) ? (((ape_loader_end - ape_loader) + (CONSTANT(COMMONPAGESIZE)) - 1) & -(CONSTANT(COMMONPAGESIZE))) / 64 : 0) + (DEFINED(ape_loader_end) ? (((ape_loader_end - ape_loader) + (CONSTANT(COMMONPAGESIZE)) - 1) & -(CONSTANT(COMMONPAGESIZE))) / 64 : 0) * 10000)) / 10) % 10 * 0x10000 + (((DEFINED(ape_loader_end) ? (((ape_loader_end - ape_loader) + (CONSTANT(COMMONPAGESIZE)) - 1) & -(CONSTANT(COMMONPAGESIZE))) / 64 : 0) + (DEFINED(ape_loader_end) ? (((ape_loader_end - ape_loader) + (CONSTANT(COMMONPAGESIZE)) - 1) & -(CONSTANT(COMMONPAGESIZE))) / 64 : 0) * 10000)) % 10 * 0x1000000 : 0xffffffffffffffff) | 0x10 : (DEFINED(ape_loader_end) ? (((ape_loader_end - ape_loader) + (CONSTANT(COMMONPAGESIZE)) - 1) & -(CONSTANT(COMMONPAGESIZE))) / 64 : 0) < 100000 ? ((((((DEFINED(ape_loader_end) ? (((ape_loader_end - ape_loader) + (CONSTANT(COMMONPAGESIZE)) - 1) & -(CONSTANT(COMMONPAGESIZE))) / 64 : 0) / 10) + ((DEFINED(ape_loader_end) ? (((ape_loader_end - ape_loader) + (CONSTANT(COMMONPAGESIZE)) - 1) & -(CONSTANT(COMMONPAGESIZE))) / 64 : 0) / 10) * 10000))) < 10000 ? 0x20202020 : ((((DEFINED(ape_loader_end) ? (((ape_loader_end - ape_loader) + (CONSTANT(COMMONPAGESIZE)) - 1) & -(CONSTANT(COMMONPAGESIZE))) / 64 : 0) / 10) + ((DEFINED(ape_loader_end) ? (((ape_loader_end - ape_loader) + (CONSTANT(COMMONPAGESIZE)) - 1) & -(CONSTANT(COMMONPAGESIZE))) / 64 : 0) / 10) * 10000)) < 100000 ? 0x20202030 + ((((DEFINED(ape_loader_end) ? (((ape_loader_end - ape_loader) + (CONSTANT(COMMONPAGESIZE)) - 1) & -(CONSTANT(COMMONPAGESIZE))) / 64 : 0) / 10) + ((DEFINED(ape_loader_end) ? (((ape_loader_end - ape_loader) + (CONSTANT(COMMONPAGESIZE)) - 1) & -(CONSTANT(COMMONPAGESIZE))) / 64 : 0) / 10) * 10000)) % 10 : ((((DEFINED(ape_loader_end) ? (((ape_loader_end - ape_loader) + (CONSTANT(COMMONPAGESIZE)) - 1) & -(CONSTANT(COMMONPAGESIZE))) / 64 : 0) / 10) + ((DEFINED(ape_loader_end) ? (((ape_loader_end - ape_loader) + (CONSTANT(COMMONPAGESIZE)) - 1) & -(CONSTANT(COMMONPAGESIZE))) / 64 : 0) / 10) * 10000)) < 1000000 ? 0x20203030 + (((((DEFINED(ape_loader_end) ? (((ape_loader_end - ape_loader) + (CONSTANT(COMMONPAGESIZE)) - 1) & -(CONSTANT(COMMONPAGESIZE))) / 64 : 0) / 10) + ((DEFINED(ape_loader_end) ? (((ape_loader_end - ape_loader) + (CONSTANT(COMMONPAGESIZE)) - 1) & -(CONSTANT(COMMONPAGESIZE))) / 64 : 0) / 10) * 10000)) / 10) % 10 + ((((DEFINED(ape_loader_end) ? (((ape_loader_end - ape_loader) + (CONSTANT(COMMONPAGESIZE)) - 1) & -(CONSTANT(COMMONPAGESIZE))) / 64 : 0) / 10) + ((DEFINED(ape_loader_end) ? (((ape_loader_end - ape_loader) + (CONSTANT(COMMONPAGESIZE)) - 1) & -(CONSTANT(COMMONPAGESIZE))) / 64 : 0) / 10) * 10000)) % 10 * 0x100 : ((((DEFINED(ape_loader_end) ? (((ape_loader_end - ape_loader) + (CONSTANT(COMMONPAGESIZE)) - 1) & -(CONSTANT(COMMONPAGESIZE))) / 64 : 0) / 10) + ((DEFINED(ape_loader_end) ? (((ape_loader_end - ape_loader) + (CONSTANT(COMMONPAGESIZE)) - 1) & -(CONSTANT(COMMONPAGESIZE))) / 64 : 0) / 10) * 10000)) < 10000000 ? 0x20303030 + (((((DEFINED(ape_loader_end) ? (((ape_loader_end - ape_loader) + (CONSTANT(COMMONPAGESIZE)) - 1) & -(CONSTANT(COMMONPAGESIZE))) / 64 : 0) / 10) + ((DEFINED(ape_loader_end) ? (((ape_loader_end - ape_loader) + (CONSTANT(COMMONPAGESIZE)) - 1) & -(CONSTANT(COMMONPAGESIZE))) / 64 : 0) / 10) * 10000)) / 100) % 10 + (((((DEFINED(ape_loader_end) ? (((ape_loader_end - ape_loader) + (CONSTANT(COMMONPAGESIZE)) - 1) & -(CONSTANT(COMMONPAGESIZE))) / 64 : 0) / 10) + ((DEFINED(ape_loader_end) ? (((ape_loader_end - ape_loader) + (CONSTANT(COMMONPAGESIZE)) - 1) & -(CONSTANT(COMMONPAGESIZE))) / 64 : 0) / 10) * 10000)) / 10) % 10 * 0x100 + ((((DEFINED(ape_loader_end) ? (((ape_loader_end - ape_loader) + (CONSTANT(COMMONPAGESIZE)) - 1) & -(CONSTANT(COMMONPAGESIZE))) / 64 : 0) / 10) + ((DEFINED(ape_loader_end) ? (((ape_loader_end - ape_loader) + (CONSTANT(COMMONPAGESIZE)) - 1) & -(CONSTANT(COMMONPAGESIZE))) / 64 : 0) / 10) * 10000)) % 10 * 0x10000 : ((((DEFINED(ape_loader_end) ? (((ape_loader_end - ape_loader) + (CONSTANT(COMMONPAGESIZE)) - 1) & -(CONSTANT(COMMONPAGESIZE))) / 64 : 0) / 10) + ((DEFINED(ape_loader_end) ? (((ape_loader_end - ape_loader) + (CONSTANT(COMMONPAGESIZE)) - 1) & -(CONSTANT(COMMONPAGESIZE))) / 64 : 0) / 10) * 10000)) < 100000000 ? 0x30303030 + (((((DEFINED(ape_loader_end) ? (((ape_loader_end - ape_loader) + (CONSTANT(COMMONPAGESIZE)) - 1) & -(CONSTANT(COMMONPAGESIZE))) / 64 : 0) / 10) + ((DEFINED(ape_loader_end) ? (((ape_loader_end - ape_loader) + (CONSTANT(COMMONPAGESIZE)) - 1) & -(CONSTANT(COMMONPAGESIZE))) / 64 : 0) / 10) * 10000)) / 1000) % 10 + (((((DEFINED(ape_loader_end) ? (((ape_loader_end - ape_loader) + (CONSTANT(COMMONPAGESIZE)) - 1) & -(CONSTANT(COMMONPAGESIZE))) / 64 : 0) / 10) + ((DEFINED(ape_loader_end) ? (((ape_loader_end - ape_loader) + (CONSTANT(COMMONPAGESIZE)) - 1) & -(CONSTANT(COMMONPAGESIZE))) / 64 : 0) / 10) * 10000)) / 100) % 10 * 0x100 + (((((DEFINED(ape_loader_end) ? (((ape_loader_end - ape_loader) + (CONSTANT(COMMONPAGESIZE)) - 1) & -(CONSTANT(COMMONPAGESIZE))) / 64 : 0) / 10) + ((DEFINED(ape_loader_end) ? (((ape_loader_end - ape_loader) + (CONSTANT(COMMONPAGESIZE)) - 1) & -(CONSTANT(COMMONPAGESIZE))) / 64 : 0) / 10) * 10000)) / 10) % 10 * 0x10000 + ((((DEFINED(ape_loader_end) ? (((ape_loader_end - ape_loader) + (CONSTANT(COMMONPAGESIZE)) - 1) & -(CONSTANT(COMMONPAGESIZE))) / 64 : 0) / 10) + ((DEFINED(ape_loader_end) ? (((ape_loader_end - ape_loader) + (CONSTANT(COMMONPAGESIZE)) - 1) & -(CONSTANT(COMMONPAGESIZE))) / 64 : 0) / 10) * 10000)) % 10 * 0x1000000 : 0xffffffffffffffff) : (DEFINED(ape_loader_end) ? (((ape_loader_end - ape_loader) + (CONSTANT(COMMONPAGESIZE)) - 1) & -(CONSTANT(COMMONPAGESIZE))) / 64 : 0) < 1000000 ? ((((((DEFINED(ape_loader_end) ? (((ape_loader_end - ape_loader) + (CONSTANT(COMMONPAGESIZE)) - 1) & -(CONSTANT(COMMONPAGESIZE))) / 64 : 0) / 100) + ((DEFINED(ape_loader_end) ? (((ape_loader_end - ape_loader) + (CONSTANT(COMMONPAGESIZE)) - 1) & -(CONSTANT(COMMONPAGESIZE))) / 64 : 0) / 100) * 10000))) < 10000 ? 0x20202020 : ((((DEFINED(ape_loader_end) ? (((ape_loader_end - ape_loader) + (CONSTANT(COMMONPAGESIZE)) - 1) & -(CONSTANT(COMMONPAGESIZE))) / 64 : 0) / 100) + ((DEFINED(ape_loader_end) ? (((ape_loader_end - ape_loader) + (CONSTANT(COMMONPAGESIZE)) - 1) & -(CONSTANT(COMMONPAGESIZE))) / 64 : 0) / 100) * 10000)) < 100000 ? 0x20202030 + ((((DEFINED(ape_loader_end) ? (((ape_loader_end - ape_loader) + (CONSTANT(COMMONPAGESIZE)) - 1) & -(CONSTANT(COMMONPAGESIZE))) / 64 : 0) / 100) + ((DEFINED(ape_loader_end) ? (((ape_loader_end - ape_loader) + (CONSTANT(COMMONPAGESIZE)) - 1) & -(CONSTANT(COMMONPAGESIZE))) / 64 : 0) / 100) * 10000)) % 10 : ((((DEFINED(ape_loader_end) ? (((ape_loader_end - ape_loader) + (CONSTANT(COMMONPAGESIZE)) - 1) & -(CONSTANT(COMMONPAGESIZE))) / 64 : 0) / 100) + ((DEFINED(ape_loader_end) ? (((ape_loader_end - ape_loader) + (CONSTANT(COMMONPAGESIZE)) - 1) & -(CONSTANT(COMMONPAGESIZE))) / 64 : 0) / 100) * 10000)) < 1000000 ? 0x20203030 + (((((DEFINED(ape_loader_end) ? (((ape_loader_end - ape_loader) + (CONSTANT(COMMONPAGESIZE)) - 1) & -(CONSTANT(COMMONPAGESIZE))) / 64 : 0) / 100) + ((DEFINED(ape_loader_end) ? (((ape_loader_end - ape_loader) + (CONSTANT(COMMONPAGESIZE)) - 1) & -(CONSTANT(COMMONPAGESIZE))) / 64 : 0) / 100) * 10000)) / 10) % 10 + ((((DEFINED(ape_loader_end) ? (((ape_loader_end - ape_loader) + (CONSTANT(COMMONPAGESIZE)) - 1) & -(CONSTANT(COMMONPAGESIZE))) / 64 : 0) / 100) + ((DEFINED(ape_loader_end) ? (((ape_loader_end - ape_loader) + (CONSTANT(COMMONPAGESIZE)) - 1) & -(CONSTANT(COMMONPAGESIZE))) / 64 : 0) / 100) * 10000)) % 10 * 0x100 : ((((DEFINED(ape_loader_end) ? (((ape_loader_end - ape_loader) + (CONSTANT(COMMONPAGESIZE)) - 1) & -(CONSTANT(COMMONPAGESIZE))) / 64 : 0) / 100) + ((DEFINED(ape_loader_end) ? (((ape_loader_end - ape_loader) + (CONSTANT(COMMONPAGESIZE)) - 1) & -(CONSTANT(COMMONPAGESIZE))) / 64 : 0) / 100) * 10000)) < 10000000 ? 0x20303030 + (((((DEFINED(ape_loader_end) ? (((ape_loader_end - ape_loader) + (CONSTANT(COMMONPAGESIZE)) - 1) & -(CONSTANT(COMMONPAGESIZE))) / 64 : 0) / 100) + ((DEFINED(ape_loader_end) ? (((ape_loader_end - ape_loader) + (CONSTANT(COMMONPAGESIZE)) - 1) & -(CONSTANT(COMMONPAGESIZE))) / 64 : 0) / 100) * 10000)) / 100) % 10 + (((((DEFINED(ape_loader_end) ? (((ape_loader_end - ape_loader) + (CONSTANT(COMMONPAGESIZE)) - 1) & -(CONSTANT(COMMONPAGESIZE))) / 64 : 0) / 100) + ((DEFINED(ape_loader_end) ? (((ape_loader_end - ape_loader) + (CONSTANT(COMMONPAGESIZE)) - 1) & -(CONSTANT(COMMONPAGESIZE))) / 64 : 0) / 100) * 10000)) / 10) % 10 * 0x100 + ((((DEFINED(ape_loader_end) ? (((ape_loader_end - ape_loader) + (CONSTANT(COMMONPAGESIZE)) - 1) & -(CONSTANT(COMMONPAGESIZE))) / 64 : 0) / 100) + ((DEFINED(ape_loader_end) ? (((ape_loader_end - ape_loader) + (CONSTANT(COMMONPAGESIZE)) - 1) & -(CONSTANT(COMMONPAGESIZE))) / 64 : 0) / 100) * 10000)) % 10 * 0x10000 : ((((DEFINED(ape_loader_end) ? (((ape_loader_end - ape_loader) + (CONSTANT(COMMONPAGESIZE)) - 1) & -(CONSTANT(COMMONPAGESIZE))) / 64 : 0) / 100) + ((DEFINED(ape_loader_end) ? (((ape_loader_end - ape_loader) + (CONSTANT(COMMONPAGESIZE)) - 1) & -(CONSTANT(COMMONPAGESIZE))) / 64 : 0) / 100) * 10000)) < 100000000 ? 0x30303030 + (((((DEFINED(ape_loader_end) ? (((ape_loader_end - ape_loader) + (CONSTANT(COMMONPAGESIZE)) - 1) & -(CONSTANT(COMMONPAGESIZE))) / 64 : 0) / 100) + ((DEFINED(ape_loader_end) ? (((ape_loader_end - ape_loader) + (CONSTANT(COMMONPAGESIZE)) - 1) & -(CONSTANT(COMMONPAGESIZE))) / 64 : 0) / 100) * 10000)) / 1000) % 10 + (((((DEFINED(ape_loader_end) ? (((ape_loader_end - ape_loader) + (CONSTANT(COMMONPAGESIZE)) - 1) & -(CONSTANT(COMMONPAGESIZE))) / 64 : 0) / 100) + ((DEFINED(ape_loader_end) ? (((ape_loader_end - ape_loader) + (CONSTANT(COMMONPAGESIZE)) - 1) & -(CONSTANT(COMMONPAGESIZE))) / 64 : 0) / 100) * 10000)) / 100) % 10 * 0x100 + (((((DEFINED(ape_loader_end) ? (((ape_loader_end - ape_loader) + (CONSTANT(COMMONPAGESIZE)) - 1) & -(CONSTANT(COMMONPAGESIZE))) / 64 : 0) / 100) + ((DEFINED(ape_loader_end) ? (((ape_loader_end - ape_loader) + (CONSTANT(COMMONPAGESIZE)) - 1) & -(CONSTANT(COMMONPAGESIZE))) / 64 : 0) / 100) * 10000)) / 10) % 10 * 0x10000 + ((((DEFINED(ape_loader_end) ? (((ape_loader_end - ape_loader) + (CONSTANT(COMMONPAGESIZE)) - 1) & -(CONSTANT(COMMONPAGESIZE))) / 64 : 0) / 100) + ((DEFINED(ape_loader_end) ? (((ape_loader_end - ape_loader) + (CONSTANT(COMMONPAGESIZE)) - 1) & -(CONSTANT(COMMONPAGESIZE))) / 64 : 0) / 100) * 10000)) % 10 * 0x1000000 : 0xffffffffffffffff) : (DEFINED(ape_loader_end) ? (((ape_loader_end - ape_loader) + (CONSTANT(COMMONPAGESIZE)) - 1) & -(CONSTANT(COMMONPAGESIZE))) / 64 : 0) < 10000000 ? ((((((DEFINED(ape_loader_end) ? (((ape_loader_end - ape_loader) + (CONSTANT(COMMONPAGESIZE)) - 1) & -(CONSTANT(COMMONPAGESIZE))) / 64 : 0) / 1000) + ((DEFINED(ape_loader_end) ? (((ape_loader_end - ape_loader) + (CONSTANT(COMMONPAGESIZE)) - 1) & -(CONSTANT(COMMONPAGESIZE))) / 64 : 0) / 1000) * 10000))) < 10000 ? 0x20202020 : ((((DEFINED(ape_loader_end) ? (((ape_loader_end - ape_loader) + (CONSTANT(COMMONPAGESIZE)) - 1) & -(CONSTANT(COMMONPAGESIZE))) / 64 : 0) / 1000) + ((DEFINED(ape_loader_end) ? (((ape_loader_end - ape_loader) + (CONSTANT(COMMONPAGESIZE)) - 1) & -(CONSTANT(COMMONPAGESIZE))) / 64 : 0) / 1000) * 10000)) < 100000 ? 0x20202030 + ((((DEFINED(ape_loader_end) ? (((ape_loader_end - ape_loader) + (CONSTANT(COMMONPAGESIZE)) - 1) & -(CONSTANT(COMMONPAGESIZE))) / 64 : 0) / 1000) + ((DEFINED(ape_loader_end) ? (((ape_loader_end - ape_loader) + (CONSTANT(COMMONPAGESIZE)) - 1) & -(CONSTANT(COMMONPAGESIZE))) / 64 : 0) / 1000) * 10000)) % 10 : ((((DEFINED(ape_loader_end) ? (((ape_loader_end - ape_loader) + (CONSTANT(COMMONPAGESIZE)) - 1) & -(CONSTANT(COMMONPAGESIZE))) / 64 : 0) / 1000) + ((DEFINED(ape_loader_end) ? (((ape_loader_end - ape_loader) + (CONSTANT(COMMONPAGESIZE)) - 1) & -(CONSTANT(COMMONPAGESIZE))) / 64 : 0) / 1000) * 10000)) < 1000000 ? 0x20203030 + (((((DEFINED(ape_loader_end) ? (((ape_loader_end - ape_loader) + (CONSTANT(COMMONPAGESIZE)) - 1) & -(CONSTANT(COMMONPAGESIZE))) / 64 : 0) / 1000) + ((DEFINED(ape_loader_end) ? (((ape_loader_end - ape_loader) + (CONSTANT(COMMONPAGESIZE)) - 1) & -(CONSTANT(COMMONPAGESIZE))) / 64 : 0) / 1000) * 10000)) / 10) % 10 + ((((DEFINED(ape_loader_end) ? (((ape_loader_end - ape_loader) + (CONSTANT(COMMONPAGESIZE)) - 1) & -(CONSTANT(COMMONPAGESIZE))) / 64 : 0) / 1000) + ((DEFINED(ape_loader_end) ? (((ape_loader_end - ape_loader) + (CONSTANT(COMMONPAGESIZE)) - 1) & -(CONSTANT(COMMONPAGESIZE))) / 64 : 0) / 1000) * 10000)) % 10 * 0x100 : ((((DEFINED(ape_loader_end) ? (((ape_loader_end - ape_loader) + (CONSTANT(COMMONPAGESIZE)) - 1) & -(CONSTANT(COMMONPAGESIZE))) / 64 : 0) / 1000) + ((DEFINED(ape_loader_end) ? (((ape_loader_end - ape_loader) + (CONSTANT(COMMONPAGESIZE)) - 1) & -(CONSTANT(COMMONPAGESIZE))) / 64 : 0) / 1000) * 10000)) < 10000000 ? 0x20303030 + (((((DEFINED(ape_loader_end) ? (((ape_loader_end - ape_loader) + (CONSTANT(COMMONPAGESIZE)) - 1) & -(CONSTANT(COMMONPAGESIZE))) / 64 : 0) / 1000) + ((DEFINED(ape_loader_end) ? (((ape_loader_end - ape_loader) + (CONSTANT(COMMONPAGESIZE)) - 1) & -(CONSTANT(COMMONPAGESIZE))) / 64 : 0) / 1000) * 10000)) / 100) % 10 + (((((DEFINED(ape_loader_end) ? (((ape_loader_end - ape_loader) + (CONSTANT(COMMONPAGESIZE)) - 1) & -(CONSTANT(COMMONPAGESIZE))) / 64 : 0) / 1000) + ((DEFINED(ape_loader_end) ? (((ape_loader_end - ape_loader) + (CONSTANT(COMMONPAGESIZE)) - 1) & -(CONSTANT(COMMONPAGESIZE))) / 64 : 0) / 1000) * 10000)) / 10) % 10 * 0x100 + ((((DEFINED(ape_loader_end) ? (((ape_loader_end - ape_loader) + (CONSTANT(COMMONPAGESIZE)) - 1) & -(CONSTANT(COMMONPAGESIZE))) / 64 : 0) / 1000) + ((DEFINED(ape_loader_end) ? (((ape_loader_end - ape_loader) + (CONSTANT(COMMONPAGESIZE)) - 1) & -(CONSTANT(COMMONPAGESIZE))) / 64 : 0) / 1000) * 10000)) % 10 * 0x10000 : ((((DEFINED(ape_loader_end) ? (((ape_loader_end - ape_loader) + (CONSTANT(COMMONPAGESIZE)) - 1) & -(CONSTANT(COMMONPAGESIZE))) / 64 : 0) / 1000) + ((DEFINED(ape_loader_end) ? (((ape_loader_end - ape_loader) + (CONSTANT(COMMONPAGESIZE)) - 1) & -(CONSTANT(COMMONPAGESIZE))) / 64 : 0) / 1000) * 10000)) < 100000000 ? 0x30303030 + (((((DEFINED(ape_loader_end) ? (((ape_loader_end - ape_loader) + (CONSTANT(COMMONPAGESIZE)) - 1) & -(CONSTANT(COMMONPAGESIZE))) / 64 : 0) / 1000) + ((DEFINED(ape_loader_end) ? (((ape_loader_end - ape_loader) + (CONSTANT(COMMONPAGESIZE)) - 1) & -(CONSTANT(COMMONPAGESIZE))) / 64 : 0) / 1000) * 10000)) / 1000) % 10 + (((((DEFINED(ape_loader_end) ? (((ape_loader_end - ape_loader) + (CONSTANT(COMMONPAGESIZE)) - 1) & -(CONSTANT(COMMONPAGESIZE))) / 64 : 0) / 1000) + ((DEFINED(ape_loader_end) ? (((ape_loader_end - ape_loader) + (CONSTANT(COMMONPAGESIZE)) - 1) & -(CONSTANT(COMMONPAGESIZE))) / 64 : 0) / 1000) * 10000)) / 100) % 10 * 0x100 + (((((DEFINED(ape_loader_end) ? (((ape_loader_end - ape_loader) + (CONSTANT(COMMONPAGESIZE)) - 1) & -(CONSTANT(COMMONPAGESIZE))) / 64 : 0) / 1000) + ((DEFINED(ape_loader_end) ? (((ape_loader_end - ape_loader) + (CONSTANT(COMMONPAGESIZE)) - 1) & -(CONSTANT(COMMONPAGESIZE))) / 64 : 0) / 1000) * 10000)) / 10) % 10 * 0x10000 + ((((DEFINED(ape_loader_end) ? (((ape_loader_end - ape_loader) + (CONSTANT(COMMONPAGESIZE)) - 1) & -(CONSTANT(COMMONPAGESIZE))) / 64 : 0) / 1000) + ((DEFINED(ape_loader_end) ? (((ape_loader_end - ape_loader) + (CONSTANT(COMMONPAGESIZE)) - 1) & -(CONSTANT(COMMONPAGESIZE))) / 64 : 0) / 1000) * 10000)) % 10 * 0x1000000 : 0xffffffffffffffff) : (DEFINED(ape_loader_end) ? (((ape_loader_end - ape_loader) + (CONSTANT(COMMONPAGESIZE)) - 1) & -(CONSTANT(COMMONPAGESIZE))) / 64 : 0) < 100000000 ? ((((((DEFINED(ape_loader_end) ? (((ape_loader_end - ape_loader) + (CONSTANT(COMMONPAGESIZE)) - 1) & -(CONSTANT(COMMONPAGESIZE))) / 64 : 0) / 10000) + ((DEFINED(ape_loader_end) ? (((ape_loader_end - ape_loader) + (CONSTANT(COMMONPAGESIZE)) - 1) & -(CONSTANT(COMMONPAGESIZE))) / 64 : 0) / 10000) * 10000))) < 10000 ? 0x20202020 : ((((DEFINED(ape_loader_end) ? (((ape_loader_end - ape_loader) + (CONSTANT(COMMONPAGESIZE)) - 1) & -(CONSTANT(COMMONPAGESIZE))) / 64 : 0) / 10000) + ((DEFINED(ape_loader_end) ? (((ape_loader_end - ape_loader) + (CONSTANT(COMMONPAGESIZE)) - 1) & -(CONSTANT(COMMONPAGESIZE))) / 64 : 0) / 10000) * 10000)) < 100000 ? 0x20202030 + ((((DEFINED(ape_loader_end) ? (((ape_loader_end - ape_loader) + (CONSTANT(COMMONPAGESIZE)) - 1) & -(CONSTANT(COMMONPAGESIZE))) / 64 : 0) / 10000) + ((DEFINED(ape_loader_end) ? (((ape_loader_end - ape_loader) + (CONSTANT(COMMONPAGESIZE)) - 1) & -(CONSTANT(COMMONPAGESIZE))) / 64 : 0) / 10000) * 10000)) % 10 : ((((DEFINED(ape_loader_end) ? (((ape_loader_end - ape_loader) + (CONSTANT(COMMONPAGESIZE)) - 1) & -(CONSTANT(COMMONPAGESIZE))) / 64 : 0) / 10000) + ((DEFINED(ape_loader_end) ? (((ape_loader_end - ape_loader) + (CONSTANT(COMMONPAGESIZE)) - 1) & -(CONSTANT(COMMONPAGESIZE))) / 64 : 0) / 10000) * 10000)) < 1000000 ? 0x20203030 + (((((DEFINED(ape_loader_end) ? (((ape_loader_end - ape_loader) + (CONSTANT(COMMONPAGESIZE)) - 1) & -(CONSTANT(COMMONPAGESIZE))) / 64 : 0) / 10000) + ((DEFINED(ape_loader_end) ? (((ape_loader_end - ape_loader) + (CONSTANT(COMMONPAGESIZE)) - 1) & -(CONSTANT(COMMONPAGESIZE))) / 64 : 0) / 10000) * 10000)) / 10) % 10 + ((((DEFINED(ape_loader_end) ? (((ape_loader_end - ape_loader) + (CONSTANT(COMMONPAGESIZE)) - 1) & -(CONSTANT(COMMONPAGESIZE))) / 64 : 0) / 10000) + ((DEFINED(ape_loader_end) ? (((ape_loader_end - ape_loader) + (CONSTANT(COMMONPAGESIZE)) - 1) & -(CONSTANT(COMMONPAGESIZE))) / 64 : 0) / 10000) * 10000)) % 10 * 0x100 : ((((DEFINED(ape_loader_end) ? (((ape_loader_end - ape_loader) + (CONSTANT(COMMONPAGESIZE)) - 1) & -(CONSTANT(COMMONPAGESIZE))) / 64 : 0) / 10000) + ((DEFINED(ape_loader_end) ? (((ape_loader_end - ape_loader) + (CONSTANT(COMMONPAGESIZE)) - 1) & -(CONSTANT(COMMONPAGESIZE))) / 64 : 0) / 10000) * 10000)) < 10000000 ? 0x20303030 + (((((DEFINED(ape_loader_end) ? (((ape_loader_end - ape_loader) + (CONSTANT(COMMONPAGESIZE)) - 1) & -(CONSTANT(COMMONPAGESIZE))) / 64 : 0) / 10000) + ((DEFINED(ape_loader_end) ? (((ape_loader_end - ape_loader) + (CONSTANT(COMMONPAGESIZE)) - 1) & -(CONSTANT(COMMONPAGESIZE))) / 64 : 0) / 10000) * 10000)) / 100) % 10 + (((((DEFINED(ape_loader_end) ? (((ape_loader_end - ape_loader) + (CONSTANT(COMMONPAGESIZE)) - 1) & -(CONSTANT(COMMONPAGESIZE))) / 64 : 0) / 10000) + ((DEFINED(ape_loader_end) ? (((ape_loader_end - ape_loader) + (CONSTANT(COMMONPAGESIZE)) - 1) & -(CONSTANT(COMMONPAGESIZE))) / 64 : 0) / 10000) * 10000)) / 10) % 10 * 0x100 + ((((DEFINED(ape_loader_end) ? (((ape_loader_end - ape_loader) + (CONSTANT(COMMONPAGESIZE)) - 1) & -(CONSTANT(COMMONPAGESIZE))) / 64 : 0) / 10000) + ((DEFINED(ape_loader_end) ? (((ape_loader_end - ape_loader) + (CONSTANT(COMMONPAGESIZE)) - 1) & -(CONSTANT(COMMONPAGESIZE))) / 64 : 0) / 10000) * 10000)) % 10 * 0x10000 : ((((DEFINED(ape_loader_end) ? (((ape_loader_end - ape_loader) + (CONSTANT(COMMONPAGESIZE)) - 1) & -(CONSTANT(COMMONPAGESIZE))) / 64 : 0) / 10000) + ((DEFINED(ape_loader_end) ? (((ape_loader_end - ape_loader) + (CONSTANT(COMMONPAGESIZE)) - 1) & -(CONSTANT(COMMONPAGESIZE))) / 64 : 0) / 10000) * 10000)) < 100000000 ? 0x30303030 + (((((DEFINED(ape_loader_end) ? (((ape_loader_end - ape_loader) + (CONSTANT(COMMONPAGESIZE)) - 1) & -(CONSTANT(COMMONPAGESIZE))) / 64 : 0) / 10000) + ((DEFINED(ape_loader_end) ? (((ape_loader_end - ape_loader) + (CONSTANT(COMMONPAGESIZE)) - 1) & -(CONSTANT(COMMONPAGESIZE))) / 64 : 0) / 10000) * 10000)) / 1000) % 10 + (((((DEFINED(ape_loader_end) ? (((ape_loader_end - ape_loader) + (CONSTANT(COMMONPAGESIZE)) - 1) & -(CONSTANT(COMMONPAGESIZE))) / 64 : 0) / 10000) + ((DEFINED(ape_loader_end) ? (((ape_loader_end - ape_loader) + (CONSTANT(COMMONPAGESIZE)) - 1) & -(CONSTANT(COMMONPAGESIZE))) / 64 : 0) / 10000) * 10000)) / 100) % 10 * 0x100 + (((((DEFINED(ape_loader_end) ? (((ape_loader_end - ape_loader) + (CONSTANT(COMMONPAGESIZE)) - 1) & -(CONSTANT(COMMONPAGESIZE))) / 64 : 0) / 10000) + ((DEFINED(ape_loader_end) ? (((ape_loader_end - ape_loader) + (CONSTANT(COMMONPAGESIZE)) - 1) & -(CONSTANT(COMMONPAGESIZE))) / 64 : 0) / 10000) * 10000)) / 10) % 10 * 0x10000 + ((((DEFINED(ape_loader_end) ? (((ape_loader_end - ape_loader) + (CONSTANT(COMMONPAGESIZE)) - 1) & -(CONSTANT(COMMONPAGESIZE))) / 64 : 0) / 10000) + ((DEFINED(ape_loader_end) ? (((ape_loader_end - ape_loader) + (CONSTANT(COMMONPAGESIZE)) - 1) & -(CONSTANT(COMMONPAGESIZE))) / 64 : 0) / 10000) * 10000)) % 10 * 0x1000000 : 0xffffffffffffffff) : 0xffffffffffffffff)); HIDDEN(ape_loader_dd_count_bcs1 = (((DEFINED(ape_loader_end) ? (((ape_loader_end - ape_loader) + (CONSTANT(COMMONPAGESIZE)) - 1) & -(CONSTANT(COMMONPAGESIZE))) / 64 : 0)) < 10000 ? 0x20202020 : (DEFINED(ape_loader_end) ? (((ape_loader_end - ape_loader) + (CONSTANT(COMMONPAGESIZE)) - 1) & -(CONSTANT(COMMONPAGESIZE))) / 64 : 0) < 100000 ? 0x20202030 + (DEFINED(ape_loader_end) ? (((ape_loader_end - ape_loader) + (CONSTANT(COMMONPAGESIZE)) - 1) & -(CONSTANT(COMMONPAGESIZE))) / 64 : 0) % 10 : (DEFINED(ape_loader_end) ? (((ape_loader_end - ape_loader) + (CONSTANT(COMMONPAGESIZE)) - 1) & -(CONSTANT(COMMONPAGESIZE))) / 64 : 0) < 1000000 ? 0x20203030 + ((DEFINED(ape_loader_end) ? (((ape_loader_end - ape_loader) + (CONSTANT(COMMONPAGESIZE)) - 1) & -(CONSTANT(COMMONPAGESIZE))) / 64 : 0) / 10) % 10 + (DEFINED(ape_loader_end) ? (((ape_loader_end - ape_loader) + (CONSTANT(COMMONPAGESIZE)) - 1) & -(CONSTANT(COMMONPAGESIZE))) / 64 : 0) % 10 * 0x100 : (DEFINED(ape_loader_end) ? (((ape_loader_end - ape_loader) + (CONSTANT(COMMONPAGESIZE)) - 1) & -(CONSTANT(COMMONPAGESIZE))) / 64 : 0) < 10000000 ? 0x20303030 + ((DEFINED(ape_loader_end) ? (((ape_loader_end - ape_loader) + (CONSTANT(COMMONPAGESIZE)) - 1) & -(CONSTANT(COMMONPAGESIZE))) / 64 : 0) / 100) % 10 + ((DEFINED(ape_loader_end) ? (((ape_loader_end - ape_loader) + (CONSTANT(COMMONPAGESIZE)) - 1) & -(CONSTANT(COMMONPAGESIZE))) / 64 : 0) / 10) % 10 * 0x100 + (DEFINED(ape_loader_end) ? (((ape_loader_end - ape_loader) + (CONSTANT(COMMONPAGESIZE)) - 1) & -(CONSTANT(COMMONPAGESIZE))) / 64 : 0) % 10 * 0x10000 : (DEFINED(ape_loader_end) ? (((ape_loader_end - ape_loader) + (CONSTANT(COMMONPAGESIZE)) - 1) & -(CONSTANT(COMMONPAGESIZE))) / 64 : 0) < 100000000 ? 0x30303030 + ((DEFINED(ape_loader_end) ? (((ape_loader_end - ape_loader) + (CONSTANT(COMMONPAGESIZE)) - 1) & -(CONSTANT(COMMONPAGESIZE))) / 64 : 0) / 1000) % 10 + ((DEFINED(ape_loader_end) ? (((ape_loader_end - ape_loader) + (CONSTANT(COMMONPAGESIZE)) - 1) & -(CONSTANT(COMMONPAGESIZE))) / 64 : 0) / 100) % 10 * 0x100 + ((DEFINED(ape_loader_end) ? (((ape_loader_end - ape_loader) + (CONSTANT(COMMONPAGESIZE)) - 1) & -(CONSTANT(COMMONPAGESIZE))) / 64 : 0) / 10) % 10 * 0x10000 + (DEFINED(ape_loader_end) ? (((ape_loader_end - ape_loader) + (CONSTANT(COMMONPAGESIZE)) - 1) & -(CONSTANT(COMMONPAGESIZE))) / 64 : 0) % 10 * 0x1000000 : 0xffffffffffffffff));
ASSERT(DEFINED(ape_mz) ? ape_mz == 0x400000 : 1, "linker panic");
ASSERT((DEFINED(__init_bss_end) ? __init_bss_end : 0) % 8 == 0,
       "__init_bss misalign");
ASSERT(((DEFINED(__init_rodata_end) ? __init_rodata_end : 0) %
        8 == 0),
       "__init_rodata misalign");
ASSERT((!DEFINED(ape_grub) ? 1 : ((ape_grub) - (0x400000)) < 8192),
       "grub stub needs to be in first 8kb of image");
ASSERT((!((ape_stack_memsz) & ((ape_stack_memsz) - 1))),
       "ape_stack_memsz must be a two power");
ASSERT(ape_stack_vaddr % ape_stack_memsz == 0,
       "ape_stack_vaddr must have ape_stack_memsz alignment; try using STATIC_STACK_ADDR(0x700000040000 & -ape_stack_memsz);");
ASSERT(ALIGNOF(.tdata) <= 64 && ALIGNOF(.tbss) <= 64,
       "_Thread_local _Alignof can't exceed TLS_ALIGNMENT");
ASSERT(DEFINED(main), "main() function not defined");
